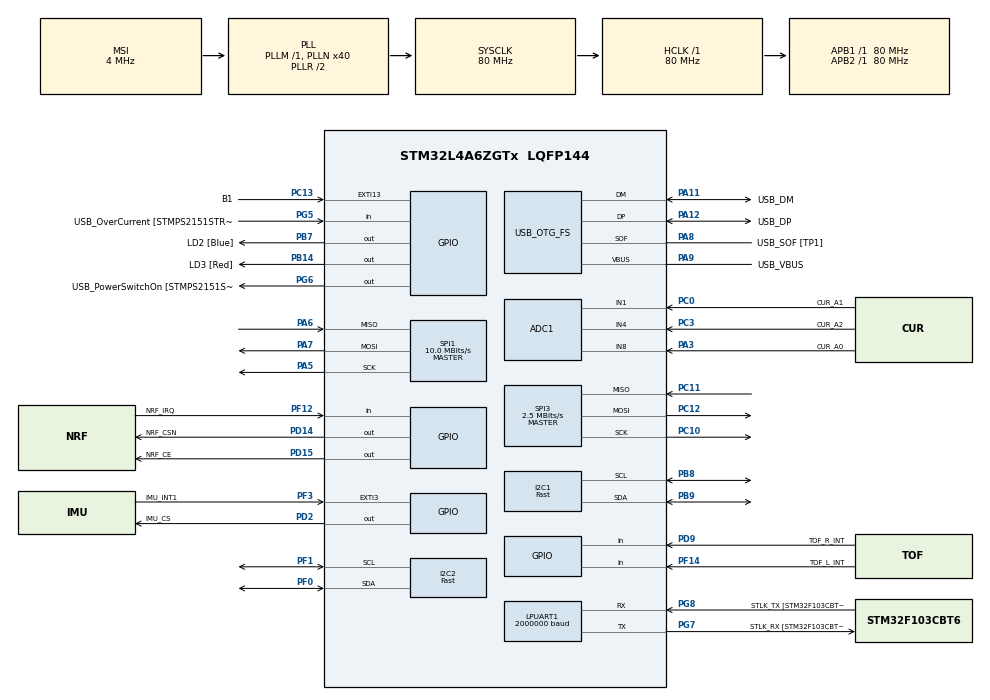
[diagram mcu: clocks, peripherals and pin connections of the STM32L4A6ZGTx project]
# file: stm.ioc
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ADC1.Channel-0\#ChannelRegularConversion=ADC_CHANNEL_8
ADC1.Channel-1\#ChannelRegularConversion=ADC_CHANNEL_1
ADC1.Channel-2\#ChannelRegularConversion=ADC_CHANNEL_4
ADC1.Channel-3\#ChannelRegularConversion=ADC_CHANNEL_VREFINT
ADC1.ClockPrescaler=ADC_CLOCK_ASYNC_DIV1
ADC1.ContinuousConvMode=ENABLE
ADC1.DMAContinuousRequests=ENABLE
ADC1.EOCSelection=ADC_EOC_SEQ_CONV
ADC1.NbrOfConversion=4
ADC1.NbrOfConversionFlag=1
ADC1.OffsetNumber-0\#ChannelRegularConversion=ADC_OFFSET_NONE
ADC1.OffsetNumber-1\#ChannelRegularConversion=ADC_OFFSET_NONE
ADC1.OffsetNumber-2\#ChannelRegularConversion=ADC_OFFSET_NONE
ADC1.OffsetNumber-3\#ChannelRegularConversion=ADC_OFFSET_NONE
ADC1.Overrun=ADC_OVR_DATA_OVERWRITTEN
ADC1.OversamplingMode=ENABLE
ADC1.OversamplingStopReset=ADC_REGOVERSAMPLING_CONTINUED_MODE
ADC1.Rank-0\#ChannelRegularConversion=1
ADC1.Rank-1\#ChannelRegularConversion=2
ADC1.Rank-2\#ChannelRegularConversion=3
ADC1.Rank-3\#ChannelRegularConversion=4
ADC1.Ratio=ADC_OVERSAMPLING_RATIO_256
ADC1.RightBitShift=ADC_RIGHTBITSHIFT_4
ADC1.SamplingTime-0\#ChannelRegularConversion=ADC_SAMPLETIME_247CYCLES_5
ADC1.SamplingTime-1\#ChannelRegularConversion=ADC_SAMPLETIME_247CYCLES_5
ADC1.SamplingTime-2\#ChannelRegularConversion=ADC_SAMPLETIME_247CYCLES_5
ADC1.SamplingTime-3\#ChannelRegularConversion=ADC_SAMPLETIME_247CYCLES_5
ADC1.ScanConvMode=ADC_SCAN_ENABLE
ADC1.TriggeredMode=ADC_TRIGGEREDMODE_SINGLE_TRIGGER
ADC1.master=1
Dma.ADC1.4.Direction=DMA_PERIPH_TO_MEMORY
Dma.ADC1.4.Instance=DMA1_Channel1
Dma.ADC1.4.MemDataAlignment=DMA_MDATAALIGN_HALFWORD
Dma.ADC1.4.MemInc=DMA_MINC_ENABLE
Dma.ADC1.4.Mode=DMA_CIRCULAR
Dma.ADC1.4.PeriphDataAlignment=DMA_PDATAALIGN_HALFWORD
Dma.ADC1.4.PeriphInc=DMA_PINC_DISABLE
Dma.ADC1.4.Priority=DMA_PRIORITY_LOW
Dma.I2C1_RX.5.Direction=DMA_PERIPH_TO_MEMORY
Dma.I2C1_RX.5.Instance=DMA1_Channel7
Dma.I2C1_RX.5.MemDataAlignment=DMA_MDATAALIGN_BYTE
Dma.I2C1_RX.5.MemInc=DMA_MINC_ENABLE
Dma.I2C1_RX.5.Mode=DMA_NORMAL
Dma.I2C1_RX.5.PeriphDataAlignment=DMA_PDATAALIGN_BYTE
Dma.I2C1_RX.5.PeriphInc=DMA_PINC_DISABLE
Dma.I2C1_RX.5.Priority=DMA_PRIORITY_MEDIUM
Dma.I2C1_TX.6.Direction=DMA_MEMORY_TO_PERIPH
Dma.I2C1_TX.6.Instance=DMA1_Channel6
Dma.I2C1_TX.6.MemDataAlignment=DMA_MDATAALIGN_BYTE
Dma.I2C1_TX.6.MemInc=DMA_MINC_ENABLE
Dma.I2C1_TX.6.Mode=DMA_NORMAL
Dma.I2C1_TX.6.PeriphDataAlignment=DMA_PDATAALIGN_BYTE
Dma.I2C1_TX.6.PeriphInc=DMA_PINC_DISABLE
Dma.I2C1_TX.6.Priority=DMA_PRIORITY_LOW
Dma.I2C2_RX.9.Direction=DMA_PERIPH_TO_MEMORY
Dma.I2C2_RX.9.Instance=DMA1_Channel5
Dma.I2C2_RX.9.MemDataAlignment=DMA_MDATAALIGN_BYTE
Dma.I2C2_RX.9.MemInc=DMA_MINC_ENABLE
Dma.I2C2_RX.9.Mode=DMA_NORMAL
Dma.I2C2_RX.9.PeriphDataAlignment=DMA_PDATAALIGN_BYTE
Dma.I2C2_RX.9.PeriphInc=DMA_PINC_DISABLE
Dma.I2C2_RX.9.Priority=DMA_PRIORITY_MEDIUM
Dma.I2C2_TX.10.Direction=DMA_MEMORY_TO_PERIPH
Dma.I2C2_TX.10.Instance=DMA1_Channel4
Dma.I2C2_TX.10.MemDataAlignment=DMA_MDATAALIGN_BYTE
Dma.I2C2_TX.10.MemInc=DMA_MINC_ENABLE
Dma.I2C2_TX.10.Mode=DMA_NORMAL
Dma.I2C2_TX.10.PeriphDataAlignment=DMA_PDATAALIGN_BYTE
Dma.I2C2_TX.10.PeriphInc=DMA_PINC_DISABLE
Dma.I2C2_TX.10.Priority=DMA_PRIORITY_LOW
Dma.LPUART_RX.0.Direction=DMA_PERIPH_TO_MEMORY
Dma.LPUART_RX.0.Instance=DMA2_Channel7
Dma.LPUART_RX.0.MemDataAlignment=DMA_MDATAALIGN_BYTE
Dma.LPUART_RX.0.MemInc=DMA_MINC_ENABLE
Dma.LPUART_RX.0.Mode=DMA_CIRCULAR
Dma.LPUART_RX.0.PeriphDataAlignment=DMA_PDATAALIGN_BYTE
Dma.LPUART_RX.0.PeriphInc=DMA_PINC_DISABLE
Dma.LPUART_RX.0.Priority=DMA_PRIORITY_HIGH
Dma.LPUART_TX.3.Direction=DMA_MEMORY_TO_PERIPH
Dma.LPUART_TX.3.Instance=DMA2_Channel6
Dma.LPUART_TX.3.MemDataAlignment=DMA_MDATAALIGN_BYTE
Dma.LPUART_TX.3.MemInc=DMA_MINC_ENABLE
Dma.LPUART_TX.3.Mode=DMA_NORMAL
Dma.LPUART_TX.3.PeriphDataAlignment=DMA_PDATAALIGN_BYTE
Dma.LPUART_TX.3.PeriphInc=DMA_PINC_DISABLE
Dma.LPUART_TX.3.Priority=DMA_PRIORITY_LOW
Dma.Request0=LPUART_RX
Dma.Request1=SPI1_RX
Dma.Request10=I2C2_TX
Dma.Request2=SPI1_TX
Dma.Request3=LPUART_TX
Dma.Request4=ADC1
Dma.Request5=I2C1_RX
Dma.Request6=I2C1_TX
Dma.Request7=SPI3_RX
Dma.Request8=SPI3_TX
Dma.Request9=I2C2_RX
Dma.SPI1_RX.1.Direction=DMA_PERIPH_TO_MEMORY
Dma.SPI1_RX.1.Instance=DMA1_Channel2
Dma.SPI1_RX.1.MemDataAlignment=DMA_MDATAALIGN_BYTE
Dma.SPI1_RX.1.MemInc=DMA_MINC_ENABLE
Dma.SPI1_RX.1.Mode=DMA_NORMAL
Dma.SPI1_RX.1.PeriphDataAlignment=DMA_PDATAALIGN_BYTE
Dma.SPI1_RX.1.PeriphInc=DMA_PINC_DISABLE
Dma.SPI1_RX.1.Priority=DMA_PRIORITY_VERY_HIGH
Dma.SPI1_TX.2.Direction=DMA_MEMORY_TO_PERIPH
Dma.SPI1_TX.2.Instance=DMA1_Channel3
Dma.SPI1_TX.2.MemDataAlignment=DMA_MDATAALIGN_BYTE
Dma.SPI1_TX.2.MemInc=DMA_MINC_ENABLE
Dma.SPI1_TX.2.Mode=DMA_NORMAL
Dma.SPI1_TX.2.PeriphDataAlignment=DMA_PDATAALIGN_BYTE
Dma.SPI1_TX.2.PeriphInc=DMA_PINC_DISABLE
Dma.SPI1_TX.2.Priority=DMA_PRIORITY_HIGH
Dma.SPI3_RX.7.Direction=DMA_PERIPH_TO_MEMORY
Dma.SPI3_RX.7.Instance=DMA2_Channel1
Dma.SPI3_RX.7.MemDataAlignment=DMA_MDATAALIGN_BYTE
Dma.SPI3_RX.7.MemInc=DMA_MINC_ENABLE
Dma.SPI3_RX.7.Mode=DMA_NORMAL
Dma.SPI3_RX.7.PeriphDataAlignment=DMA_PDATAALIGN_BYTE
Dma.SPI3_RX.7.PeriphInc=DMA_PINC_DISABLE
Dma.SPI3_RX.7.Priority=DMA_PRIORITY_VERY_HIGH
Dma.SPI3_TX.8.Direction=DMA_MEMORY_TO_PERIPH
Dma.SPI3_TX.8.Instance=DMA2_Channel2
Dma.SPI3_TX.8.MemDataAlignment=DMA_MDATAALIGN_BYTE
Dma.SPI3_TX.8.MemInc=DMA_MINC_ENABLE
Dma.SPI3_TX.8.Mode=DMA_NORMAL
Dma.SPI3_TX.8.PeriphDataAlignment=DMA_PDATAALIGN_BYTE
Dma.SPI3_TX.8.PeriphInc=DMA_PINC_DISABLE
Dma.SPI3_TX.8.Priority=DMA_PRIORITY_HIGH
I2C1.I2C_Speed_Mode=I2C_Fast
I2C1.Timing=0x00702991
I2C2.I2C_Speed_Mode=I2C_Fast
I2C2.Timing=0x00702991
LPUART1.AutoBaudRateEnableParam=UART_ADVFEATURE_AUTOBAUDRATE_DISABLE
LPUART1.BaudRate=2000000
LPUART1.DMADisableonRxErrorParam=UART_ADVFEATURE_DMA_ENABLEONRXERROR
LPUART1.DataInvertParam=UART_ADVFEATURE_DATAINV_DISABLE
LPUART1.MSBFirstParam=UART_ADVFEATURE_MSBFIRST_DISABLE
LPUART1.Mode=UART_MODE_TX_RX
LPUART1.OneBitSampling=UART_ONE_BIT_SAMPLE_DISABLE
LPUART1.OverrunDisableParam=UART_ADVFEATURE_OVERRUN_DISABLE
LPUART1.Parity=UART_PARITY_NONE
LPUART1.RxPinLevelInvertParam=UART_ADVFEATURE_RXINV_DISABLE
LPUART1.StopBits=UART_STOPBITS_1
LPUART1.SwapParam=UART_ADVFEATURE_SWAP_DISABLE
LPUART1.TxPinLevelInvertParam=UART_ADVFEATURE_TXINV_DISABLE
LPUART1.WordLength=UART_WORDLENGTH_8B
Mcu.Family=STM32L4
Mcu.Name=STM32L4A6ZGTx
Mcu.Package=LQFP144
NVIC.DMA1_Channel1_IRQn=true\:0\:0\:false\:false\:true\:false\:true\:true
NVIC.DMA1_Channel2_IRQn=true\:0\:0\:false\:false\:true\:false\:true\:true
NVIC.DMA1_Channel3_IRQn=true\:0\:0\:false\:false\:true\:false\:true\:true
NVIC.DMA1_Channel4_IRQn=true\:0\:0\:false\:false\:true\:false\:true\:true
NVIC.DMA1_Channel5_IRQn=true\:0\:0\:false\:false\:true\:false\:true\:true
NVIC.DMA1_Channel6_IRQn=true\:0\:0\:false\:false\:true\:false\:true\:true
NVIC.DMA1_Channel7_IRQn=true\:0\:0\:false\:false\:true\:false\:true\:true
NVIC.DMA2_Channel1_IRQn=true\:0\:0\:false\:false\:true\:false\:true\:true
NVIC.DMA2_Channel2_IRQn=true\:0\:0\:false\:false\:true\:false\:true\:true
NVIC.DMA2_Channel6_IRQn=true\:0\:0\:false\:false\:true\:false\:true\:true
NVIC.DMA2_Channel7_IRQn=true\:0\:0\:false\:false\:true\:false\:true\:true
NVIC.EXTI3_IRQn=true\:0\:0\:false\:false\:true\:true\:true\:true
NVIC.I2C1_ER_IRQn=true\:1\:0\:false\:false\:true\:true\:true\:true
NVIC.I2C1_EV_IRQn=true\:1\:0\:false\:false\:true\:true\:true\:true
NVIC.I2C2_ER_IRQn=true\:1\:0\:false\:false\:true\:true\:true\:true
NVIC.I2C2_EV_IRQn=true\:1\:0\:false\:false\:true\:true\:true\:true
NVIC.LPUART1_IRQn=true\:1\:0\:false\:false\:true\:true\:true\:true
NVIC.PriorityGroup=NVIC_PRIORITYGROUP_4
NVIC.SPI1_IRQn=true\:1\:0\:false\:false\:true\:true\:true\:true
PA10.GPIO_Label=USB_ID
PA10.Signal=USB_OTG_FS_ID
PA11.GPIO_Label=USB_DM
PA11.Mode=Device_Only
PA11.Signal=USB_OTG_FS_DM
PA12.GPIO_Label=USB_DP
PA12.Mode=Device_Only
PA12.Signal=USB_OTG_FS_DP
PA13\ (JTMS/SWDIO).GPIO_Label=TMS
PA13\ (JTMS/SWDIO).Mode=Trace_Asynchronous_SW
PA13\ (JTMS/SWDIO).Signal=SYS_JTMS-SWDIO
PA14\ (JTCK/SWCLK).GPIO_Label=TCK
PA14\ (JTCK/SWCLK).Mode=Trace_Asynchronous_SW
PA14\ (JTCK/SWCLK).Signal=SYS_JTCK-SWCLK
PA3.GPIO_Label=CUR_A0
PA3.Signal=ADCx_IN8
PA5.Mode=Full_Duplex_Master
PA5.Signal=SPI1_SCK
PA6.Mode=Full_Duplex_Master
PA6.Signal=SPI1_MISO
PA7.Mode=Full_Duplex_Master
PA7.Signal=SPI1_MOSI
PA8.GPIO_Label=USB_SOF [TP1]
PA8.Mode=Activate_SOF_FS
PA8.Signal=USB_OTG_FS_SOF
PA9.GPIO_Label=USB_VBUS
PA9.Mode=Activate_VBUS
PA9.Signal=USB_OTG_FS_VBUS
PB14.GPIO_Label=LD3 [Red]
PB14.Signal=GPIO_Output
PB3\ (JTDO/TRACESWO).GPIO_Label=SWO
PB3\ (JTDO/TRACESWO).Mode=Trace_Asynchronous_SW
PB3\ (JTDO/TRACESWO).Signal=SYS_JTDO-SWO
PB7.GPIO_Label=LD2 [Blue]
PB7.Signal=GPIO_Output
PB8.Mode=I2C
PB8.Signal=I2C1_SCL
PB9.Mode=I2C
PB9.Signal=I2C1_SDA
PC0.GPIO_Label=CUR_A1
PC0.Signal=ADCx_IN1
PC10.Mode=Full_Duplex_Master
PC10.Signal=SPI3_SCK
PC11.Mode=Full_Duplex_Master
PC11.Signal=SPI3_MISO
PC12.Mode=Full_Duplex_Master
PC12.Signal=SPI3_MOSI
PC13.GPIO_Label=B1
PC13.Signal=GPXTI13
PC14-OSC32_IN\ (PC14).Mode=LSE-External-Oscillator
PC14-OSC32_IN\ (PC14).Signal=RCC_OSC32_IN
PC15-OSC32_OUT\ (PC15).Mode=LSE-External-Oscillator
PC15-OSC32_OUT\ (PC15).Signal=RCC_OSC32_OUT
PC3.GPIO_Label=CUR_A2
PC3.Signal=ADCx_IN4
PD14.GPIO_Label=NRF_CSN
PD14.PinState=GPIO_PIN_SET
PD14.Signal=GPIO_Output
PD15.GPIO_Label=NRF_CE
PD15.Signal=GPIO_Output
PD2.GPIO_Label=IMU_CS
PD2.PinState=GPIO_PIN_SET
PD2.Signal=GPIO_Output
PD9.GPIO_Label=TOF_R_INT
PD9.Signal=GPIO_Input
PF0.Mode=I2C
PF0.Signal=I2C2_SDA
PF1.Mode=I2C
PF1.Signal=I2C2_SCL
PF12.GPIO_Label=NRF_IRQ
PF12.GPIO_PuPd=GPIO_PULLUP
PF12.Signal=GPIO_Input
PF14.GPIO_Label=TOF_L_INT
PF14.Signal=GPIO_Input
PF3.GPIO_Label=IMU_INT1
PF3.GPIO_ModeDefaultEXTI=GPIO_MODE_IT_RISING
PF3.Signal=GPXTI3
PG5.GPIO_Label=USB_OverCurrent [STMPS2151STR_FAULT]
PG5.Signal=GPIO_Input
PG6.GPIO_Label=USB_PowerSwitchOn [STMPS2151STR_EN]
PG6.Signal=GPIO_Output
PG7.GPIO_Label=STLK_RX [STM32F103CBT6_PA3]
PG7.Mode=Asynchronous
PG7.Signal=LPUART1_TX
PG8.GPIO_Label=STLK_TX [STM32F103CBT6_PA2]
PG8.Mode=Asynchronous
PG8.Signal=LPUART1_RX
PH1-OSC_OUT\ (PH1).Signal=RCC_OSC_OUT
ProjectManager.HeapSize=0x200
ProjectManager.StackSize=0x400
ProjectManager.TargetToolchain=CMake
RCC.ADCFreq_Value=48000000
RCC.AHBFreq_Value=80000000
RCC.APB1CLKDivider=RCC_HCLK_DIV1
RCC.APB1Freq_Value=80000000
RCC.APB1TimFreq_Value=80000000
RCC.APB2Freq_Value=80000000
RCC.APB2TimFreq_Value=80000000
RCC.CortexFreq_Value=80000000
RCC.FLatency=FLASH_LATENCY_4
RCC.HCLKFreq_Value=80000000
RCC.HSE_VALUE=8000000
RCC.HSI48_VALUE=48000000
RCC.HSI_VALUE=16000000
RCC.MSI_VALUE=4000000
RCC.PLLN=40
RCC.PLLR=RCC_PLLR_DIV2
RCC.PLLSAI1N=24
RCC.PREFETCH_ENABLE=1
RCC.SYSCLKFreq_VALUE=80000000
RCC.SYSCLKSource=RCC_SYSCLKSOURCE_PLLCLK
RCC.USBFreq_Value=48000000
RCC.VCOOutputFreq_Value=160000000
SH.ADCx_IN1.0=ADC1_IN1,IN1-Single-Ended
SH.ADCx_IN4.0=ADC1_IN4,IN4-Single-Ended
SH.ADCx_IN8.0=ADC1_IN8,IN8-Single-Ended
SPI1.BaudRatePrescaler=SPI_BAUDRATEPRESCALER_8
SPI1.CLKPhase=SPI_PHASE_1EDGE
SPI1.CLKPolarity=SPI_POLARITY_LOW
SPI1.CalculateBaudRate=10.0 MBits/s
SPI1.DataSize=SPI_DATASIZE_8BIT
SPI1.Direction=SPI_DIRECTION_2LINES
SPI1.Mode=SPI_MODE_MASTER
SPI1.VirtualType=VM_MASTER
SPI3.BaudRatePrescaler=SPI_BAUDRATEPRESCALER_32
SPI3.CLKPhase=SPI_PHASE_2EDGE
SPI3.CLKPolarity=SPI_POLARITY_HIGH
SPI3.CalculateBaudRate=2.5 MBits/s
SPI3.DataSize=SPI_DATASIZE_8BIT
SPI3.Direction=SPI_DIRECTION_2LINES
SPI3.Mode=SPI_MODE_MASTER
SPI3.VirtualType=VM_MASTER
USB_OTG_FS.Sof_enable=ENABLE
USB_OTG_FS.VirtualMode=Device_Only
USB_OTG_FS.battery_charging_enable=ENABLE
USB_OTG_FS.low_power_enable=DISABLE
USB_OTG_FS.lpm_enable=DISABLE
USB_OTG_FS.use_dedicated_ep1=DISABLE
USB_OTG_FS.vbus_sensing_enable=ENABLE
VP_ADC1_Vref_Input.Mode=IN-Vrefint
board=NUCLEO-L4A6ZG

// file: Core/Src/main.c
/* USER CODE BEGIN Header */
/**
  ******************************************************************************
  * @file           : main.c
  * @brief          : Main program body
  ******************************************************************************
  * @attention
  *
  * Copyright (c) 2026 STMicroelectronics.
  * All rights reserved.
  *
  * This software is licensed under terms that can be found in the LICENSE file
  * in the root directory of this software component.
  * If no LICENSE file comes with this software, it is provided AS-IS.
  *
  ******************************************************************************
  */
/* USER CODE END Header */
#include "main.h"

/* USER CODE BEGIN Includes */
#include "app_main.h"

/* USER CODE END Includes */

ADC_HandleTypeDef hadc1;
DMA_HandleTypeDef hdma_adc1;

I2C_HandleTypeDef hi2c1;
I2C_HandleTypeDef hi2c2;
DMA_HandleTypeDef hdma_i2c1_rx;
DMA_HandleTypeDef hdma_i2c1_tx;
DMA_HandleTypeDef hdma_i2c2_rx;
DMA_HandleTypeDef hdma_i2c2_tx;

UART_HandleTypeDef hlpuart1;
DMA_HandleTypeDef hdma_lpuart_rx;
DMA_HandleTypeDef hdma_lpuart_tx;

SPI_HandleTypeDef hspi1;
SPI_HandleTypeDef hspi3;
DMA_HandleTypeDef hdma_spi1_rx;
DMA_HandleTypeDef hdma_spi1_tx;
DMA_HandleTypeDef hdma_spi3_rx;
DMA_HandleTypeDef hdma_spi3_tx;

PCD_HandleTypeDef hpcd_USB_OTG_FS;

void SystemClock_Config(void);
void PeriphCommonClock_Config(void);
static void MX_GPIO_Init(void);
static void MX_DMA_Init(void);
static void MX_LPUART1_UART_Init(void);
static void MX_USB_OTG_FS_PCD_Init(void);
static void MX_SPI1_Init(void);
static void MX_ADC1_Init(void);
static void MX_SPI3_Init(void);
static void MX_I2C1_Init(void);
static void MX_I2C2_Init(void);

int main(void)
{

  /* MCU Configuration--------------------------------------------------------*/

  /* Reset of all peripherals, Initializes the Flash interface and the Systick. */
  HAL_Init();

  /* Configure the system clock */
  SystemClock_Config();

  /* Configure the peripherals common clocks */
  PeriphCommonClock_Config();

  /* Initialize all configured peripherals */
  MX_GPIO_Init();
  MX_DMA_Init();
  MX_LPUART1_UART_Init();
  MX_USB_OTG_FS_PCD_Init();
  MX_SPI1_Init();
  MX_ADC1_Init();
  MX_SPI3_Init();
  MX_I2C1_Init();
  MX_I2C2_Init();
  /* USER CODE BEGIN 2 */
  app_main(); /* C++ application, never returns (App/) */

  /* USER CODE END 2 */

  /* Infinite loop */
  while (1)
  {

  }
}

void SystemClock_Config(void)
{
  RCC_OscInitTypeDef RCC_OscInitStruct = {0};
  RCC_ClkInitTypeDef RCC_ClkInitStruct = {0};

  /** Configure the main internal regulator output voltage
  */
  if (HAL_PWREx_ControlVoltageScaling(PWR_REGULATOR_VOLTAGE_SCALE1) != HAL_OK)
  {
    Error_Handler();
  }

  /** Configure LSE Drive Capability
  */
  HAL_PWR_EnableBkUpAccess();
  __HAL_RCC_LSEDRIVE_CONFIG(RCC_LSEDRIVE_LOW);

  /** Initializes the RCC Oscillators according to the specified parameters
  * in the RCC_OscInitTypeDef structure.
  */
  RCC_OscInitStruct.OscillatorType = RCC_OSCILLATORTYPE_LSE|RCC_OSCILLATORTYPE_MSI;
  RCC_OscInitStruct.LSEState = RCC_LSE_ON;
  RCC_OscInitStruct.MSIState = RCC_MSI_ON;
  RCC_OscInitStruct.MSICalibrationValue = 0;
  RCC_OscInitStruct.MSIClockRange = RCC_MSIRANGE_6;
  RCC_OscInitStruct.PLL.PLLState = RCC_PLL_ON;
  RCC_OscInitStruct.PLL.PLLSource = RCC_PLLSOURCE_MSI;
  RCC_OscInitStruct.PLL.PLLM = 1;
  RCC_OscInitStruct.PLL.PLLN = 40;
  RCC_OscInitStruct.PLL.PLLP = RCC_PLLP_DIV2;
  RCC_OscInitStruct.PLL.PLLQ = RCC_PLLQ_DIV2;
  RCC_OscInitStruct.PLL.PLLR = RCC_PLLR_DIV2;
  if (HAL_RCC_OscConfig(&RCC_OscInitStruct) != HAL_OK)
  {
    Error_Handler();
  }

  /** Initializes the CPU, AHB and APB buses clocks
  */
  RCC_ClkInitStruct.ClockType = RCC_CLOCKTYPE_HCLK|RCC_CLOCKTYPE_SYSCLK
                              |RCC_CLOCKTYPE_PCLK1|RCC_CLOCKTYPE_PCLK2;
  RCC_ClkInitStruct.SYSCLKSource = RCC_SYSCLKSOURCE_PLLCLK;
  RCC_ClkInitStruct.AHBCLKDivider = RCC_SYSCLK_DIV1;
  RCC_ClkInitStruct.APB1CLKDivider = RCC_HCLK_DIV1;
  RCC_ClkInitStruct.APB2CLKDivider = RCC_HCLK_DIV1;

  if (HAL_RCC_ClockConfig(&RCC_ClkInitStruct, FLASH_LATENCY_4) != HAL_OK)
  {
    Error_Handler();
  }

  /** Enable MSI Auto calibration
  */
  HAL_RCCEx_EnableMSIPLLMode();
}

void PeriphCommonClock_Config(void)
{
  RCC_PeriphCLKInitTypeDef PeriphClkInit = {0};

  /** Initializes the peripherals clock
  */
  PeriphClkInit.PeriphClockSelection = RCC_PERIPHCLK_USB|RCC_PERIPHCLK_ADC;
  PeriphClkInit.AdcClockSelection = RCC_ADCCLKSOURCE_PLLSAI1;
  PeriphClkInit.UsbClockSelection = RCC_USBCLKSOURCE_PLLSAI1;
  PeriphClkInit.PLLSAI1.PLLSAI1Source = RCC_PLLSOURCE_MSI;
  PeriphClkInit.PLLSAI1.PLLSAI1M = 1;
  PeriphClkInit.PLLSAI1.PLLSAI1N = 24;
  PeriphClkInit.PLLSAI1.PLLSAI1P = RCC_PLLP_DIV2;
  PeriphClkInit.PLLSAI1.PLLSAI1Q = RCC_PLLQ_DIV2;
  PeriphClkInit.PLLSAI1.PLLSAI1R = RCC_PLLR_DIV2;
  PeriphClkInit.PLLSAI1.PLLSAI1ClockOut = RCC_PLLSAI1_48M2CLK|RCC_PLLSAI1_ADC1CLK;
  if (HAL_RCCEx_PeriphCLKConfig(&PeriphClkInit) != HAL_OK)
  {
    Error_Handler();
  }
}

static void MX_ADC1_Init(void)
{

  ADC_MultiModeTypeDef multimode = {0};
  ADC_ChannelConfTypeDef sConfig = {0};

  /** Common config
  */
  hadc1.Instance = ADC1;
  hadc1.Init.ClockPrescaler = ADC_CLOCK_ASYNC_DIV1;
  hadc1.Init.Resolution = ADC_RESOLUTION_12B;
  hadc1.Init.DataAlign = ADC_DATAALIGN_RIGHT;
  hadc1.Init.ScanConvMode = ADC_SCAN_ENABLE;
  hadc1.Init.EOCSelection = ADC_EOC_SEQ_CONV;
  hadc1.Init.LowPowerAutoWait = DISABLE;
  hadc1.Init.ContinuousConvMode = ENABLE;
  hadc1.Init.NbrOfConversion = 4;
  hadc1.Init.DiscontinuousConvMode = DISABLE;
  hadc1.Init.ExternalTrigConv = ADC_SOFTWARE_START;
  hadc1.Init.ExternalTrigConvEdge = ADC_EXTERNALTRIGCONVEDGE_NONE;
  hadc1.Init.DMAContinuousRequests = ENABLE;
  hadc1.Init.Overrun = ADC_OVR_DATA_OVERWRITTEN;
  hadc1.Init.OversamplingMode = ENABLE;
  hadc1.Init.Oversampling.Ratio = ADC_OVERSAMPLING_RATIO_256;
  hadc1.Init.Oversampling.RightBitShift = ADC_RIGHTBITSHIFT_4;
  hadc1.Init.Oversampling.TriggeredMode = ADC_TRIGGEREDMODE_SINGLE_TRIGGER;
  hadc1.Init.Oversampling.OversamplingStopReset = ADC_REGOVERSAMPLING_CONTINUED_MODE;
  if (HAL_ADC_Init(&hadc1) != HAL_OK)
  {
    Error_Handler();
  }

  /** Configure the ADC multi-mode
  */
  multimode.Mode = ADC_MODE_INDEPENDENT;
  if (HAL_ADCEx_MultiModeConfigChannel(&hadc1, &multimode) != HAL_OK)
  {
    Error_Handler();
  }

  /** Configure Regular Channel
  */
  sConfig.Channel = ADC_CHANNEL_8;
  sConfig.Rank = ADC_REGULAR_RANK_1;
  sConfig.SamplingTime = ADC_SAMPLETIME_247CYCLES_5;
  sConfig.SingleDiff = ADC_SINGLE_ENDED;
  sConfig.OffsetNumber = ADC_OFFSET_NONE;
  sConfig.Offset = 0;
  if (HAL_ADC_ConfigChannel(&hadc1, &sConfig) != HAL_OK)
  {
    Error_Handler();
  }

  /** Configure Regular Channel
  */
  sConfig.Channel = ADC_CHANNEL_1;
  sConfig.Rank = ADC_REGULAR_RANK_2;
  if (HAL_ADC_ConfigChannel(&hadc1, &sConfig) != HAL_OK)
  {
    Error_Handler();
  }

  /** Configure Regular Channel
  */
  sConfig.Channel = ADC_CHANNEL_4;
  sConfig.Rank = ADC_REGULAR_RANK_3;
  if (HAL_ADC_ConfigChannel(&hadc1, &sConfig) != HAL_OK)
  {
    Error_Handler();
  }

  /** Configure Regular Channel
  */
  sConfig.Channel = ADC_CHANNEL_VREFINT;
  sConfig.Rank = ADC_REGULAR_RANK_4;
  if (HAL_ADC_ConfigChannel(&hadc1, &sConfig) != HAL_OK)
  {
    Error_Handler();
  }

}

static void MX_I2C1_Init(void)
{

  hi2c1.Instance = I2C1;
  hi2c1.Init.Timing = 0x00702991;
  hi2c1.Init.OwnAddress1 = 0;
  hi2c1.Init.AddressingMode = I2C_ADDRESSINGMODE_7BIT;
  hi2c1.Init.DualAddressMode = I2C_DUALADDRESS_DISABLE;
  hi2c1.Init.OwnAddress2 = 0;
  hi2c1.Init.OwnAddress2Masks = I2C_OA2_NOMASK;
  hi2c1.Init.GeneralCallMode = I2C_GENERALCALL_DISABLE;
  hi2c1.Init.NoStretchMode = I2C_NOSTRETCH_DISABLE;
  if (HAL_I2C_Init(&hi2c1) != HAL_OK)
  {
    Error_Handler();
  }

  /** Configure Analogue filter
  */
  if (HAL_I2CEx_ConfigAnalogFilter(&hi2c1, I2C_ANALOGFILTER_ENABLE) != HAL_OK)
  {
    Error_Handler();
  }

  /** Configure Digital filter
  */
  if (HAL_I2CEx_ConfigDigitalFilter(&hi2c1, 0) != HAL_OK)
  {
    Error_Handler();
  }

}

static void MX_I2C2_Init(void)
{

  hi2c2.Instance = I2C2;
  hi2c2.Init.Timing = 0x00702991;
  hi2c2.Init.OwnAddress1 = 0;
  hi2c2.Init.AddressingMode = I2C_ADDRESSINGMODE_7BIT;
  hi2c2.Init.DualAddressMode = I2C_DUALADDRESS_DISABLE;
  hi2c2.Init.OwnAddress2 = 0;
  hi2c2.Init.OwnAddress2Masks = I2C_OA2_NOMASK;
  hi2c2.Init.GeneralCallMode = I2C_GENERALCALL_DISABLE;
  hi2c2.Init.NoStretchMode = I2C_NOSTRETCH_DISABLE;
  if (HAL_I2C_Init(&hi2c2) != HAL_OK)
  {
    Error_Handler();
  }

  /** Configure Analogue filter
  */
  if (HAL_I2CEx_ConfigAnalogFilter(&hi2c2, I2C_ANALOGFILTER_ENABLE) != HAL_OK)
  {
    Error_Handler();
  }

  /** Configure Digital filter
  */
  if (HAL_I2CEx_ConfigDigitalFilter(&hi2c2, 0) != HAL_OK)
  {
    Error_Handler();
  }

}

static void MX_LPUART1_UART_Init(void)
{

  hlpuart1.Instance = LPUART1;
  hlpuart1.Init.BaudRate = 2000000;
  hlpuart1.Init.WordLength = UART_WORDLENGTH_8B;
  hlpuart1.Init.StopBits = UART_STOPBITS_1;
  hlpuart1.Init.Parity = UART_PARITY_NONE;
  hlpuart1.Init.Mode = UART_MODE_TX_RX;
  hlpuart1.Init.HwFlowCtl = UART_HWCONTROL_NONE;
  hlpuart1.Init.OneBitSampling = UART_ONE_BIT_SAMPLE_DISABLE;
  hlpuart1.AdvancedInit.AdvFeatureInit = UART_ADVFEATURE_RXOVERRUNDISABLE_INIT;
  hlpuart1.AdvancedInit.OverrunDisable = UART_ADVFEATURE_OVERRUN_DISABLE;
  if (HAL_UART_Init(&hlpuart1) != HAL_OK)
  {
    Error_Handler();
  }

}

static void MX_SPI1_Init(void)
{

  /* SPI1 parameter configuration*/
  hspi1.Instance = SPI1;
  hspi1.Init.Mode = SPI_MODE_MASTER;
  hspi1.Init.Direction = SPI_DIRECTION_2LINES;
  hspi1.Init.DataSize = SPI_DATASIZE_8BIT;
  hspi1.Init.CLKPolarity = SPI_POLARITY_LOW;
  hspi1.Init.CLKPhase = SPI_PHASE_1EDGE;
  hspi1.Init.NSS = SPI_NSS_SOFT;
  hspi1.Init.BaudRatePrescaler = SPI_BAUDRATEPRESCALER_8;
  hspi1.Init.FirstBit = SPI_FIRSTBIT_MSB;
  hspi1.Init.TIMode = SPI_TIMODE_DISABLE;
  hspi1.Init.CRCCalculation = SPI_CRCCALCULATION_DISABLE;
  hspi1.Init.CRCPolynomial = 7;
  hspi1.Init.CRCLength = SPI_CRC_LENGTH_DATASIZE;
  hspi1.Init.NSSPMode = SPI_NSS_PULSE_ENABLE;
  if (HAL_SPI_Init(&hspi1) != HAL_OK)
  {
    Error_Handler();
  }

}

static void MX_SPI3_Init(void)
{

  /* SPI3 parameter configuration*/
  hspi3.Instance = SPI3;
  hspi3.Init.Mode = SPI_MODE_MASTER;
  hspi3.Init.Direction = SPI_DIRECTION_2LINES;
  hspi3.Init.DataSize = SPI_DATASIZE_8BIT;
  hspi3.Init.CLKPolarity = SPI_POLARITY_HIGH;
  hspi3.Init.CLKPhase = SPI_PHASE_2EDGE;
  hspi3.Init.NSS = SPI_NSS_SOFT;
  hspi3.Init.BaudRatePrescaler = SPI_BAUDRATEPRESCALER_32;
  hspi3.Init.FirstBit = SPI_FIRSTBIT_MSB;
  hspi3.Init.TIMode = SPI_TIMODE_DISABLE;
  hspi3.Init.CRCCalculation = SPI_CRCCALCULATION_DISABLE;
  hspi3.Init.CRCPolynomial = 7;
  hspi3.Init.CRCLength = SPI_CRC_LENGTH_DATASIZE;
  hspi3.Init.NSSPMode = SPI_NSS_PULSE_DISABLE;
  if (HAL_SPI_Init(&hspi3) != HAL_OK)
  {
    Error_Handler();
  }

}

static void MX_USB_OTG_FS_PCD_Init(void)
{

  hpcd_USB_OTG_FS.Instance = USB_OTG_FS;
  hpcd_USB_OTG_FS.Init.dev_endpoints = 6;
  hpcd_USB_OTG_FS.Init.speed = PCD_SPEED_FULL;
  hpcd_USB_OTG_FS.Init.phy_itface = PCD_PHY_EMBEDDED;
  hpcd_USB_OTG_FS.Init.Sof_enable = ENABLE;
  hpcd_USB_OTG_FS.Init.low_power_enable = DISABLE;
  hpcd_USB_OTG_FS.Init.lpm_enable = DISABLE;
  hpcd_USB_OTG_FS.Init.battery_charging_enable = ENABLE;
  hpcd_USB_OTG_FS.Init.use_dedicated_ep1 = DISABLE;
  hpcd_USB_OTG_FS.Init.vbus_sensing_enable = ENABLE;
  if (HAL_PCD_Init(&hpcd_USB_OTG_FS) != HAL_OK)
  {
    Error_Handler();
  }

}

static void MX_DMA_Init(void)
{

  /* DMA controller clock enable */
  __HAL_RCC_DMA2_CLK_ENABLE();
  __HAL_RCC_DMA1_CLK_ENABLE();

  /* DMA interrupt init */
  /* DMA1_Channel1_IRQn interrupt configuration */
  HAL_NVIC_SetPriority(DMA1_Channel1_IRQn, 0, 0);
  HAL_NVIC_EnableIRQ(DMA1_Channel1_IRQn);
  /* DMA1_Channel2_IRQn interrupt configuration */
  HAL_NVIC_SetPriority(DMA1_Channel2_IRQn, 0, 0);
  HAL_NVIC_EnableIRQ(DMA1_Channel2_IRQn);
  /* DMA1_Channel3_IRQn interrupt configuration */
  HAL_NVIC_SetPriority(DMA1_Channel3_IRQn, 0, 0);
  HAL_NVIC_EnableIRQ(DMA1_Channel3_IRQn);
  /* DMA1_Channel4_IRQn interrupt configuration */
  HAL_NVIC_SetPriority(DMA1_Channel4_IRQn, 0, 0);
  HAL_NVIC_EnableIRQ(DMA1_Channel4_IRQn);
  /* DMA1_Channel5_IRQn interrupt configuration */
  HAL_NVIC_SetPriority(DMA1_Channel5_IRQn, 0, 0);
  HAL_NVIC_EnableIRQ(DMA1_Channel5_IRQn);
  /* DMA1_Channel6_IRQn interrupt configuration */
  HAL_NVIC_SetPriority(DMA1_Channel6_IRQn, 0, 0);
  HAL_NVIC_EnableIRQ(DMA1_Channel6_IRQn);
  /* DMA1_Channel7_IRQn interrupt configuration */
  HAL_NVIC_SetPriority(DMA1_Channel7_IRQn, 0, 0);
  HAL_NVIC_EnableIRQ(DMA1_Channel7_IRQn);
  /* DMA2_Channel1_IRQn interrupt configuration */
  HAL_NVIC_SetPriority(DMA2_Channel1_IRQn, 0, 0);
  HAL_NVIC_EnableIRQ(DMA2_Channel1_IRQn);
  /* DMA2_Channel2_IRQn interrupt configuration */
  HAL_NVIC_SetPriority(DMA2_Channel2_IRQn, 0, 0);
  HAL_NVIC_EnableIRQ(DMA2_Channel2_IRQn);
  /* DMA2_Channel6_IRQn interrupt configuration */
  HAL_NVIC_SetPriority(DMA2_Channel6_IRQn, 0, 0);
  HAL_NVIC_EnableIRQ(DMA2_Channel6_IRQn);
  /* DMA2_Channel7_IRQn interrupt configuration */
  HAL_NVIC_SetPriority(DMA2_Channel7_IRQn, 0, 0);
  HAL_NVIC_EnableIRQ(DMA2_Channel7_IRQn);

}

static void MX_GPIO_Init(void)
{
  GPIO_InitTypeDef GPIO_InitStruct = {0};

  /* GPIO Ports Clock Enable */
  __HAL_RCC_GPIOC_CLK_ENABLE();
  __HAL_RCC_GPIOF_CLK_ENABLE();
  __HAL_RCC_GPIOH_CLK_ENABLE();
  __HAL_RCC_GPIOA_CLK_ENABLE();
  __HAL_RCC_GPIOB_CLK_ENABLE();
  __HAL_RCC_GPIOD_CLK_ENABLE();
  __HAL_RCC_GPIOG_CLK_ENABLE();
  HAL_PWREx_EnableVddIO2();

  /*Configure GPIO pin Output Level */
  HAL_GPIO_WritePin(GPIOB, LD3_Pin|LD2_Pin, GPIO_PIN_RESET);

  /*Configure GPIO pin Output Level */
  HAL_GPIO_WritePin(GPIOD, NRF_CSN_Pin|IMU_CS_Pin, GPIO_PIN_SET);

  /*Configure GPIO pin Output Level */
  HAL_GPIO_WritePin(NRF_CE_GPIO_Port, NRF_CE_Pin, GPIO_PIN_RESET);

  /*Configure GPIO pin Output Level */
  HAL_GPIO_WritePin(USB_PowerSwitchOn_GPIO_Port, USB_PowerSwitchOn_Pin, GPIO_PIN_RESET);

  /*Configure GPIO pin : B1_Pin */
  GPIO_InitStruct.Pin = B1_Pin;
  GPIO_InitStruct.Mode = GPIO_MODE_IT_RISING;
  GPIO_InitStruct.Pull = GPIO_NOPULL;
  HAL_GPIO_Init(B1_GPIO_Port, &GPIO_InitStruct);

  /*Configure GPIO pin : IMU_INT1_Pin */
  GPIO_InitStruct.Pin = IMU_INT1_Pin;
  GPIO_InitStruct.Mode = GPIO_MODE_IT_RISING;
  GPIO_InitStruct.Pull = GPIO_NOPULL;
  HAL_GPIO_Init(IMU_INT1_GPIO_Port, &GPIO_InitStruct);

  /*Configure GPIO pin : NRF_IRQ_Pin */
  GPIO_InitStruct.Pin = NRF_IRQ_Pin;
  GPIO_InitStruct.Mode = GPIO_MODE_INPUT;
  GPIO_InitStruct.Pull = GPIO_PULLUP;
  HAL_GPIO_Init(NRF_IRQ_GPIO_Port, &GPIO_InitStruct);

  /*Configure GPIO pin : TOF_L_INT_Pin */
  GPIO_InitStruct.Pin = TOF_L_INT_Pin;
  GPIO_InitStruct.Mode = GPIO_MODE_INPUT;
  GPIO_InitStruct.Pull = GPIO_NOPULL;
  HAL_GPIO_Init(TOF_L_INT_GPIO_Port, &GPIO_InitStruct);

  /*Configure GPIO pins : LD3_Pin LD2_Pin */
  GPIO_InitStruct.Pin = LD3_Pin|LD2_Pin;
  GPIO_InitStruct.Mode = GPIO_MODE_OUTPUT_PP;
  GPIO_InitStruct.Pull = GPIO_NOPULL;
  GPIO_InitStruct.Speed = GPIO_SPEED_FREQ_LOW;
  HAL_GPIO_Init(GPIOB, &GPIO_InitStruct);

  /*Configure GPIO pin : TOF_R_INT_Pin */
  GPIO_InitStruct.Pin = TOF_R_INT_Pin;
  GPIO_InitStruct.Mode = GPIO_MODE_INPUT;
  GPIO_InitStruct.Pull = GPIO_NOPULL;
  HAL_GPIO_Init(TOF_R_INT_GPIO_Port, &GPIO_InitStruct);

  /*Configure GPIO pins : NRF_CSN_Pin NRF_CE_Pin IMU_CS_Pin */
  GPIO_InitStruct.Pin = NRF_CSN_Pin|NRF_CE_Pin|IMU_CS_Pin;
  GPIO_InitStruct.Mode = GPIO_MODE_OUTPUT_PP;
  GPIO_InitStruct.Pull = GPIO_NOPULL;
  GPIO_InitStruct.Speed = GPIO_SPEED_FREQ_LOW;
  HAL_GPIO_Init(GPIOD, &GPIO_InitStruct);

  /*Configure GPIO pin : USB_OverCurrent_Pin */
  GPIO_InitStruct.Pin = USB_OverCurrent_Pin;
  GPIO_InitStruct.Mode = GPIO_MODE_INPUT;
  GPIO_InitStruct.Pull = GPIO_NOPULL;
  HAL_GPIO_Init(USB_OverCurrent_GPIO_Port, &GPIO_InitStruct);

  /*Configure GPIO pin : USB_PowerSwitchOn_Pin */
  GPIO_InitStruct.Pin = USB_PowerSwitchOn_Pin;
  GPIO_InitStruct.Mode = GPIO_MODE_OUTPUT_PP;
  GPIO_InitStruct.Pull = GPIO_NOPULL;
  GPIO_InitStruct.Speed = GPIO_SPEED_FREQ_LOW;
  HAL_GPIO_Init(USB_PowerSwitchOn_GPIO_Port, &GPIO_InitStruct);

  /* EXTI interrupt init*/
  HAL_NVIC_SetPriority(EXTI3_IRQn, 0, 0);
  HAL_NVIC_EnableIRQ(EXTI3_IRQn);

}

void Error_Handler(void)
{
  __disable_irq();
  while (1)
  {
  }
}
